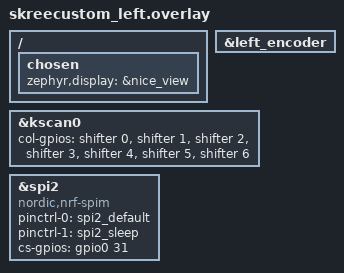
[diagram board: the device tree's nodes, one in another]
#include "skreecustom.dtsi"

&left_encoder {
	status = "okay";
};

&kscan0 {
    col-gpios
        = <&shifter 0 GPIO_ACTIVE_HIGH>
        , <&shifter 1 GPIO_ACTIVE_HIGH>
        , <&shifter 2 GPIO_ACTIVE_HIGH>
        , <&shifter 3 GPIO_ACTIVE_HIGH>
        , <&shifter 4 GPIO_ACTIVE_HIGH>
        , <&shifter 5 GPIO_ACTIVE_HIGH>
        , <&shifter 6 GPIO_ACTIVE_HIGH>
//        , <&shifter 7 GPIO_ACTIVE_HIGH>
        ;
};

nice_view_spi: &spi2 {
    compatible = "nordic,nrf-spim";
    pinctrl-0 = <&spi2_default>;
    pinctrl-1 = <&spi2_sleep>;
    pinctrl-names = "default", "sleep";
    cs-gpios = <&gpio0 31 GPIO_ACTIVE_HIGH>;
};

/ {
    chosen {
        zephyr,display = &nice_view;
    };
};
